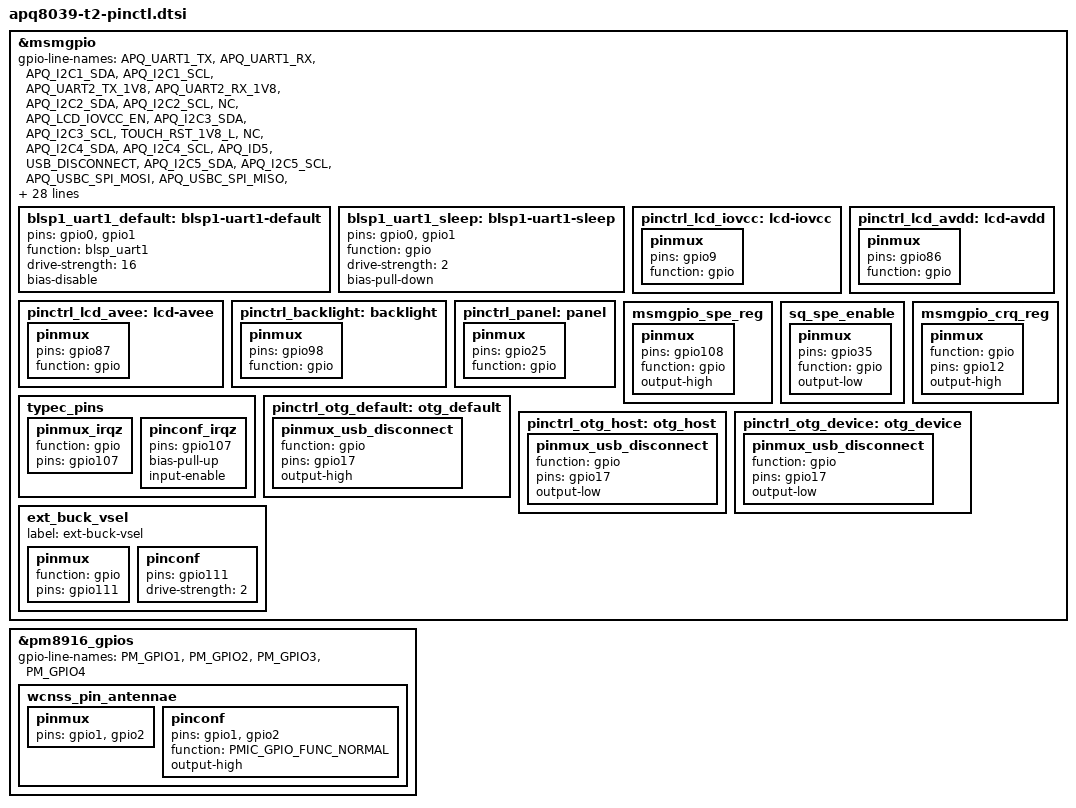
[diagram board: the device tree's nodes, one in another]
// SPDX-License-Identifier: GPL-2.0

#include <dt-bindings/gpio/gpio.h>
#include <dt-bindings/pinctrl/qcom,pmic-gpio.h>

/*
 * Line names are taken from the schematic of T2, Ver X03.
 * July 14, 2018. Page 4 in particular.
 */

&msmgpio {
	gpio-line-names =
		"APQ_UART1_TX",		/* GPIO_0 */
		"APQ_UART1_RX",
		"APQ_I2C1_SDA",
		"APQ_I2C1_SCL",
		"APQ_UART2_TX_1V8",
		"APQ_UART2_RX_1V8",
		"APQ_I2C2_SDA",
		"APQ_I2C2_SCL",
		"NC",
		"APQ_LCD_IOVCC_EN",
		"APQ_I2C3_SDA",		/* GPIO_10 */
		"APQ_I2C3_SCL",
		"TOUCH_RST_1V8_L",
		"NC",
		"APQ_I2C4_SDA",
		"APQ_I2C4_SCL",
		"APQ_ID5",
		"USB_DISCONNECT",
		"APQ_I2C5_SDA",
		"APQ_I2C5_SCL",
		"APQ_USBC_SPI_MOSI",	/* GPIO_20 */
		"APQ_USBC_SPI_MISO",
		"APQ_USBC_SPI_SS_L",
		"APQ_USBC_SPI_CLK",
		"APQ_LCD_TE0",
		"APQ_LCD_RST_L",
		"NC",
		"NC",
		"ACCELEROMETER_INT1",
		"APQ_CAM_I2C0_SDA",
		"APQ_CAM_I2C0_SCL",	/* GPIO_30 */
		"ACCELEROMETER_INT2",
		"NC",
		"NC",
		"NC",
		"APQ_K21_RST_1V8_L",
		"NC",
		"APQ_EDL_1V8",
		"TP145",
		"BT_SSBI",
		"NC",			/* GPIO_40 */
		"NC",
		"NC",
		"NC",
		"NC",
		"NC",
		"NC",
		"BT_CTRL",
		"BT_DAT",
		"PWR_GPIO_IN",
		"PWR_GPIO_OUT",		/* GPIO_50 */
		"CARD_DET_MLB_L",
		"HALL_SENSOR",
		"TP63",
		"TP64",
		"TP65",
		"NC",
		"NC",
		"NC",
		"NC",
		"NC",			/* GPIO_60 */
		"NC",
		"APQ_K21_GPIO0_1V8",
		"CDC_PDM_CLK",
		"CDC_PDM_SYNC",
		"CDC_PDM_TX",
		"CDC_PDM_RX0",
		"CDC_PDM_RX1",
		"CDC_PDM_RX2",
		"APQ_K21_GPIO1_1V8",
		"NC",			/* GPIO_70 */
		"APQ_HUB_SEL_1V8",
		"APQ_K21_GPIO2_1V8",
		"APQ_K21_GPIO3_1V8",
		"APQ_ID0",
		"APQ_ID1",
		"APQ_ID2",
		"APQ_ID3",
		"APQ_ID4",
		"APQ_HUB_SUSP_IND",
		"BOOT_CONFIG_0",	/* GPIO_80 */
		"BOOT_CONFIG_1",
		"BOOT_CONFIG_2",
		"BOOT_CONFIG_3",
		"NC",
		"NC",
		"APQ_LCD_AVDD_EN",
		"APQ_LCD_AVEE_EN",
		"TP70",
		"NC",
		"APQ_DEBUG0",		/* GPIO_90 */
		"APQ_DEBUG1",
		"APQ_DEBUG2",
		"APQ_DEBUG3",
		"TP165",
		"NC",
		"APQ_LNA_PWR_EN",
		"NC",
		"APQ_LCD_BL_EN",
		"NC",
		"APQ_LCD_ID0",		/* GPIO_100 */
		"APQ_LCD_ID1",
		"USBC_GPIO5_1V8",
		"NC",
		"NC",
		"NC",
		"APQ_HUB_RST_1V8_L",
		"USBC_I2C_IRQ_1V8_L",
		"SPE_PWR_EN",
		"NC",
		"APQ_USB_ID",		/* GPIO_110 */
		"APQ_EXT_BUCK_VSEL",
		"APQ_USB_ID_OUT",
		"NC",
		"PRNT_RST_L",
		"APQ_CRQ_I2C_RDY_1V8",
		"TYPEC_RST_1V8_H",
		"CHG_BACKPWR_EN",
		"CHG_PROCHOT_L",
		"NC",
		"USBC_GPIO7_1V8",	/* GPIO_120 */
		"NC";

	blsp1_uart1_default: blsp1-uart1-default {
		pins = "gpio0", "gpio1";
		function = "blsp_uart1";

		drive-strength = <16>;
		bias-disable;
	};

	blsp1_uart1_sleep: blsp1-uart1-sleep {
		pins = "gpio0", "gpio1";
		function = "gpio";

		drive-strength = <2>;
		bias-pull-down;
	};

	pinctrl_lcd_iovcc: lcd-iovcc {
		pinmux {
			pins = "gpio9";
			function = "gpio";
		};
	};

	pinctrl_lcd_avdd: lcd-avdd {
		pinmux {
			pins = "gpio86";
			function = "gpio";
		};
	};

	pinctrl_lcd_avee: lcd-avee {
		pinmux {
			pins = "gpio87";
			function = "gpio";
		};
	};

	pinctrl_backlight: backlight {
		pinmux {
			pins = "gpio98";
			function = "gpio";
		};
	};

	pinctrl_panel: panel {
		pinmux {
			pins = "gpio25";
			function = "gpio";
		};
	};

	msmgpio_spe_reg: msmgpio_spe_reg {
		pinmux {
			pins = "gpio108";
			function = "gpio";
			output-high;
		};
	};

	sq_spe_enable: sq_spe_enable {
		pinmux {
			pins = "gpio35";
			function = "gpio";
			output-low;
		};
	};

	msmgpio_crq_reg: msmgpio_crq_reg {
		pinmux {
			function = "gpio";
			pins = "gpio12";
			output-high;
		};
	};

	typec_pins: typec_pins {
		pinmux_irqz {
			function = "gpio";
			pins = "gpio107";
		};
		pinconf_irqz {
			pins = "gpio107";
			bias-pull-up;
			input-enable;
		};
	};

	pinctrl_otg_default: otg_default {
		pinmux_usb_disconnect {
			function = "gpio";
			pins = "gpio17";
			output-high;
		};
	};

	pinctrl_otg_host: otg_host {
		pinmux_usb_disconnect {
			function = "gpio";
			pins = "gpio17";
			output-low;
		};
	};

	pinctrl_otg_device: otg_device {
		pinmux_usb_disconnect {
			function = "gpio";
			pins = "gpio17";
			output-low;
		};
	};

	ext_buck_vsel: ext_buck_vsel {
		label = "ext-buck-vsel";
		pinmux {
			function = "gpio";
			pins = "gpio111";
		};
		pinconf {
			pins = "gpio111";
			drive-strength = <2>;
		};
	};
};

&pm8916_gpios {
	gpio-line-names =
		"PM_GPIO1",     /* WIFI_GPIO1_PRE */
		"PM_GPIO2",     /* WIFI_GPIO2_PRE */
		"PM_GPIO3",
		"PM_GPIO4";

	wcnss_pin_antennae: wcnss_pin_antennae {
		pinmux {
			pins = "gpio1", "gpio2";
		};
		pinconf {
			pins = "gpio1", "gpio2";
			function = PMIC_GPIO_FUNC_NORMAL;
			output-high;
		};
	};
};
